# RTS5921 register map
Vendor: Realtek Semiconductor Corp.; Series: RTS5921 Series; File version: 0.01
CPU: ARMV8MBL r0p0, little endian, MPU, no FPU, VTOR, 3 interrupt priority bits
Registers are 32-bit, read-write, reset 0x0 unless marked. A register's access mark holds for its fields unless they carry their own. Offsets are from the block's base; [hi:lo] are bit positions; {n}, {i} and the like mark numbered series.

## SPIM — SPI Master Controller
Base 0x40100300
Same registers: SPIS 0x40100400
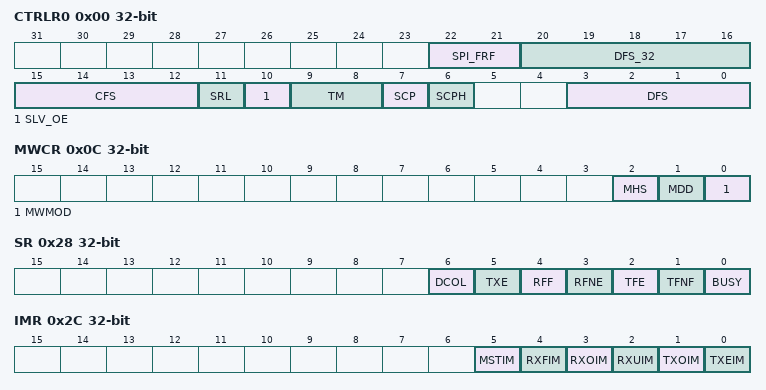
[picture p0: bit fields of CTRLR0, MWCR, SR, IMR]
0x00 CTRLR0 — Control Register 0
  [22:21] SPI_FRF — Selects the serial protocol frame format. Valid when the frame format is set to Motorola SPI.
    0=MOTOROLA_SPI (Motorola SPI Frame Format); 1=DUAL_SPI_FRF (Dual SPI Frame Format); 2=QUAD_SPI_FRF (Quad SPI Frame Format); 3=OCTAL_SPI_FRF (Octal SPI Frame Format)
  [20:16] DFS_32 — Varies Data Frame Size up to 32 bits.
    3=FRAME_04BITS (4-bit serial data transfer); 4=FRAME_05BITS (5-bit serial data transfer); 31=FRAME_32BITS (32-bit serial data transfer)
  [15:12] CFS — Control Frame Size
    0=SIZE_01_BIT (1-bit Control Word); 1=SIZE_02_BIT (2-bit Control Word); 15=SIZE_16_BIT (16-bit Control Word)
  [11] SRL — Shift Register Loop
    1=TESTING_MODE (Test mode: Tx and Rx shift reg connected); 0=NORMAL_MODE (Normal mode operation)
  [10] SLV_OE — Slave Output Enable
    1=DISABLED; 0=ENABLED
  [9:8] TM — Transmit Mode
    0=TX_AND_RX (Transmit and receive); 1=TX_ONLY (Transmit only mode or Write (SPI_FRF != 2'b00)); 3=EEPROM_READ (EEPROM Read mode)
  [7] SCP — Used to select the polarity of the inactive serial clock.
    0=SCLK_LOW (Inactive state of serial clock is low); 1=SCLK_HIGH (Inactive state of serial clock is high)
  [6] SCPH — Serial Clock Phase. Determines the capture edge of the serial clock in relation to the slave select signal.
    0=SCPH_MIDDLE (Serial clock toggles in middle of first data bit); 1=SCPH_SECOND_EDGE (Data are captured on the second edge of the serial clock)
  [3:0] DFS — Data Frame Size. Determines the size of the data transfer in serial frames.
    {v}=FRAME_{v+1:02}BITS ({v+1}-bit serial data transfer) (v=3..15)
0x04 CTRLR1 — Control Register 1
  [15:0] NDF — Number of Data Frames. Represents the total number of data frames for the transaction.
0x08 SSIENR — SSI Enable Register
  [0] SSI_EN — SSI Enable.
    0=DISABLE (Disables Serial Transfer); 1=ENABLE (Enables Serial Transfer)
0x0C MWCR — Microwire Control Register
  [2] MHS — Microwire Handshaking. Controls the handshaking interface of the Microwire.
    0=DISABLE (Handshaking interface is disabled); 1=ENABLE (Handshaking interface is enabled)
  [1] MDD — Microwire Control. Specifies the direction of data flow for SSI.
    0=RECEIVE (SSI receives data); 1=TRANSMIT (SSI transmits data)
  [0] MWMOD — Microwire Transfer Mode. Configures the transfer mode of the Microwire.
    0=NON_SEQUENTIAL (Non-Sequential Microwire Transfer); 1=SEQUENTIAL (Sequential Microwire Transfer)
0x10 SER — Slave Enable Register
0x14 BAUDR — Baud Rate Register
  [15:0] SCKDV — SSI Clock Divider. Determines the output serial clock frequency. The formula for the output clock: Fsclk_out = Fssi_clk / SCKDV.
0x18 TXFTLR — Transmit FIFO Threshold Level Register
0x1C RXFTLR — Receive FIFO Threshold Level Register
0x20 TXFLR ro — Transmit FIFO Level Register
0x24 RXFLR ro — Receive FIFO Level Register
0x28 SR ro — Status Register
  [6] DCOL — Data Collision Error. Indicates a collision occurred during transmission.
    0=NO_ERROR_CONDITION; 1=TX_COLLISION_ERROR (Transmit Data Collision Error)
  [5] TXE — Transmission Error. Indicates an error occurred during transmission.
    0=NO_ERROR; 1=TX_ERROR (Transmission Error)
  [4] RFF — Receive FIFO Full. Indicates the status of the receive FIFO.
    0=NOT_FULL (Receive FIFO is not full); 1=FULL (Receive FIFO is full)
  [3] RFNE — Receive FIFO Not Empty. Indicates if the receive FIFO contains data.
    0=EMPTY (Receive FIFO is empty); 1=NOT_EMPTY (Receive FIFO is not empty)
  [2] TFE — Transmit FIFO Empty. Indicates if the transmit FIFO is empty.
    0=NOT_EMPTY (Transmit FIFO is not empty); 1=EMPTY (Transmit FIFO is empty)
  [1] TFNF — Transmit FIFO Not Full. Indicates if the transmit FIFO is not full.
    0=FULL (Transmit FIFO is full); 1=NOT_FULL (Transmit FIFO is not full)
  [0] BUSY — SSI Busy Flag. Indicates if the SSI is actively transferring data.
    0=INACTIVE (DW_apb_ssi is idle or disabled); 1=ACTIVE (DW_apb_ssi is actively transferring data)
0x2C IMR — Interrupt Mask Register
  [5] MSTIM — Multi-Master Contention Interrupt Mask. Controls the masking of the ssi_mst_intr interrupt.
    0=MASKED (ssi_mst_intr interrupt is masked); 1=UNMASKED (ssi_mst_intr interrupt is not masked)
  [4] RXFIM — Receive FIFO Full Interrupt Mask. Controls the masking of the ssi_rxf_intr interrupt.
    0=MASKED (ssi_rxf_intr interrupt is masked); 1=UNMASKED (ssi_rxf_intr interrupt is not masked)
  [3] RXOIM — Receive FIFO Overflow Interrupt Mask. Controls the masking of the ssi_rxo_intr interrupt.
    0=MASKED (ssi_rxo_intr interrupt is masked); 1=UNMASKED (ssi_rxo_intr interrupt is not masked)
  [2] RXUIM — Receive FIFO Underflow Interrupt Mask. Controls the masking of the ssi_rxu_intr interrupt.
    0=MASKED (ssi_rxu_intr interrupt is masked); 1=UNMASKED (ssi_rxu_intr interrupt is not masked)
  [1] TXOIM — Transmit FIFO Overflow Interrupt Mask. Controls the masking of the ssi_txo_intr interrupt.
    0=MASKED (ssi_txo_intr interrupt is masked); 1=UNMASKED (ssi_txo_intr interrupt is not masked)
  [0] TXEIM — Transmit FIFO Empty Interrupt Mask. Controls the masking of the ssi_txe_intr interrupt.
    0=MASKED (ssi_txe_intr interrupt is masked); 1=UNMASKED (ssi_txe_intr interrupt is not masked)
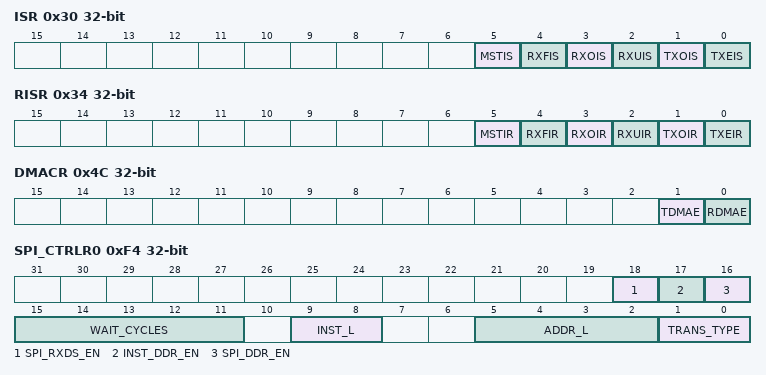
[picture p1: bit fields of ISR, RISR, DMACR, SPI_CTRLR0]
0x30 ISR ro — Interrupt Status Register
  [5] MSTIS — Multi-Master Contention Interrupt Status. Indicates the status of the ssi_mst_intr interrupt after masking.
    0=INACTIVE (ssi_mst_intr interrupt not active after masking); 1=ACTIVE (ssi_mst_intr interrupt is active after masking)
  [4] RXFIS — Receive FIFO Full Interrupt Status. Indicates the status of the ssi_rxf_intr interrupt after masking.
    0=INACTIVE (ssi_rxf_intr interrupt is not active after masking); 1=ACTIVE (ssi_rxf_intr interrupt is full after masking)
  [3] RXOIS — Receive FIFO Overflow Interrupt Status. Indicates the status of the ssi_rxo_intr interrupt after masking.
    0=INACTIVE (ssi_rxo_intr interrupt is not active after masking); 1=ACTIVE (ssi_rxo_intr interrupt is active after masking)
  [2] RXUIS — Receive FIFO Underflow Interrupt Status. Indicates the status of the ssi_rxu_intr interrupt after masking.
    0=INACTIVE (ssi_rxu_intr interrupt is not active after masking); 1=ACTIVE (ssi_rxu_intr interrupt is active after masking)
  [1] TXOIS — Transmit FIFO Overflow Interrupt Status. Indicates the status of the ssi_txo_intr interrupt after masking.
    0=INACTIVE (ssi_txo_intr interrupt is not active after masking); 1=ACTIVE (ssi_txo_intr interrupt is active after masking)
  [0] TXEIS — Transmit FIFO Empty Interrupt Status. Indicates the status of the ssi_txe_intr interrupt after masking.
    0=INACTIVE (ssi_txe_intr interrupt is not active after masking); 1=ACTIVE (ssi_txe_intr interrupt is active after masking)
0x34 RISR ro — Raw Interrupt Status Register
  [5] MSTIR — Multi-Master Contention Raw Interrupt Status. Indicates the status of the ssi_mst_intr interrupt prior to masking.
    0=INACTIVE (ssi_mst_intr interrupt is not active prior to masking); 1=ACTIVE (ssi_mst_intr interrupt is active prior to masking)
  [4] RXFIR — Receive FIFO Full Raw Interrupt Status. Indicates the status of the ssi_rxf_intr interrupt prior to masking.
    0=INACTIVE (ssi_rxf_intr interrupt is not active prior to masking); 1=ACTIVE (ssi_rxf_intr interrupt is active prior to masking)
  [3] RXOIR — Receive FIFO Overflow Raw Interrupt Status. Indicates the status of the ssi_rxo_intr interrupt prior to masking.
    0=INACTIVE (ssi_rxo_intr interrupt is not active prior to masking); 1=ACTIVE (ssi_rxo_intr interrupt is active prior to masking)
  [2] RXUIR — Receive FIFO Underflow Raw Interrupt Status. Indicates the status of the ssi_rxu_intr interrupt prior to masking.
    0=INACTIVE (ssi_rxu_intr interrupt is not active prior to masking); 1=ACTIVE (ssi_rxu_intr interrupt is active prior to masking)
  [1] TXOIR — Transmit FIFO Overflow Raw Interrupt Status. Indicates the status of the ssi_txo_intr interrupt prior to masking.
    0=INACTIVE (ssi_txo_intr interrupt is not active prior to masking); 1=ACTIVE (ssi_txo_intr interrupt is active prior to masking)
  [0] TXEIR — Transmit FIFO Empty Raw Interrupt Status. Indicates the status of the ssi_txe_intr interrupt prior to masking.
    0=INACTIVE (ssi_txe_intr interrupt is not active prior to masking); 1=ACTIVE (ssi_txe_intr interrupt is active prior to masking)
0x38 TXOICR wo — Transmit FIFO Overflow Interrupt Clear Register
0x3C RXOICR wo — Receive FIFO Overflow Interrupt Clear Register
0x40 RXUICR wo — Receive FIFO Underflow Interrupt Clear Register
0x44 MSTICR wo — Multi-Master Interrupt Clear Register
0x48 ICR wo — Interrupt Clear Register
0x4C DMACR — DMA Control Register
  [1] TDMAE — Transmit DMA Enable. Controls the enable status of the transmit DMA operation.
    0=DISABLE (Transmit DMA disabled); 1=ENABLE (Transmit DMA enabled)
  [0] RDMAE — Receive DMA Enable. Controls the enable status of the receive DMA operation.
    0=DISABLE (Receive DMA disabled); 1=ENABLE (Receive DMA enabled)
0x50 DMATDLR — DMA Transmit Data Level Register
0x54 DMARDLR — DMA Receive Data Level Register
0x58 IDR ro — Identification Register
0x5C SSI_VERSION_ID ro
0x60 DR — Data Register
0xF0 RX_SAMPLE_DLY — Receive Sample Delay Register
0xF4 SPI_CTRLR0 — SPI Control Register
  [18] SPI_RXDS_EN — Read data strobe enable bit.
  [17] INST_DDR_EN — Instruction DDR Enable bit.
  [16] SPI_DDR_EN — SPI DDR Enable bit.
  [15:11] WAIT_CYCLES
  [9:8] INST_L — Instruction Length.
    0=0-bit (No Instruction); 1=4-bit Instruction; 2=8-bit Instruction; 3=16-bit Instruction
  [5:2] ADDR_L — Address Length.
    0=0-bit Address Width; 1=4-bit Address Width; 2=8-bit Address Width; 3=12-bit Address Width; 4=16-bit Address Width; 5=20-bit Address Width; 6=24-bit Address Width; 7=28-bit Address Width; 8=32-bit Address Width; 9=36-bit Address Width; 10=40-bit Address Width; 11=44-bit Address Width; 12=48-bit Address Width; 13=52-bit Address Width; 14=56-bit Address Width; 15=60-bit Address Width
  [1:0] TRANS_TYPE — Address and instruction transfer format.
    0=STANDARD_SPI (Instruction and Address will be sent in Standard SPI Mode.); 1=ADDR_SPECIFIED_MODE (Instruction sent in Standard SPI Mode, Address sent in mode specified by CTRLR0.SPI_FRF.); 2=BOTH_SPECIFIED_MODE (Both Instruction and Address sent in the mode specified by SPI_FRF.); 3=NO_USED
0xF8 TXD_DRIVE_EDGE — Transmit Drive Edge Register
